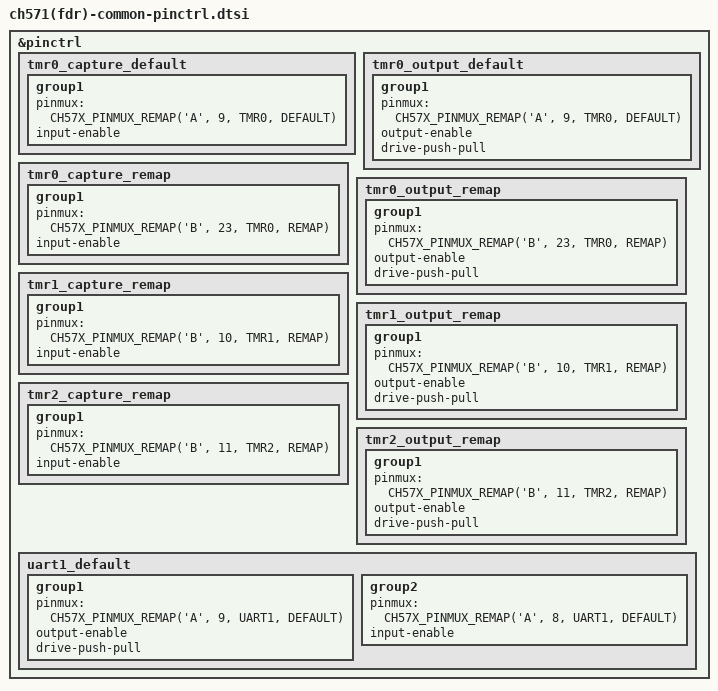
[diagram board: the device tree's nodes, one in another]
/*
 * Copyright (c) 2023 Chen Xingyu <hi@xingrz.me>
 * SPDX-License-Identifier: Apache-2.0
 */

#include <wch/ch57x/ch57x-common-pinctrl.dtsi>
#include <wch/ch57x/ch571-common-pinctrl.dtsi>

&pinctrl {
	/omit-if-no-ref/ tmr0_capture_default: tmr0_capture_default {
		group1 {
			pinmux = <CH57X_PINMUX_REMAP('A', 9, TMR0, DEFAULT)>; /* TMR0 */
			input-enable;
		};
	};

	/omit-if-no-ref/ tmr0_output_default: tmr0_output_default {
		group1 {
			pinmux = <CH57X_PINMUX_REMAP('A', 9, TMR0, DEFAULT)>; /* TMR0 */
			output-enable;
			drive-push-pull;
		};
	};

	/omit-if-no-ref/ tmr0_capture_remap: tmr0_capture_remap {
		group1 {
			pinmux = <CH57X_PINMUX_REMAP('B', 23, TMR0, REMAP)>; /* TMR0_ */
			input-enable;
		};
	};

	/omit-if-no-ref/ tmr0_output_remap: tmr0_output_remap {
		group1 {
			pinmux = <CH57X_PINMUX_REMAP('B', 23, TMR0, REMAP)>; /* TMR0_ */
			output-enable;
			drive-push-pull;
		};
	};

	/omit-if-no-ref/ tmr1_capture_remap: tmr1_capture_remap {
		group1 {
			pinmux = <CH57X_PINMUX_REMAP('B', 10, TMR1, REMAP)>; /* TMR1_ */
			input-enable;
		};
	};

	/omit-if-no-ref/ tmr1_output_remap: tmr1_output_remap {
		group1 {
			pinmux = <CH57X_PINMUX_REMAP('B', 10, TMR1, REMAP)>; /* TMR1_ */
			output-enable;
			drive-push-pull;
		};
	};

	/omit-if-no-ref/ tmr2_capture_remap: tmr2_capture_remap {
		group1 {
			pinmux = <CH57X_PINMUX_REMAP('B', 11, TMR2, REMAP)>; /* TMR2_ */
			input-enable;
		};
	};

	/omit-if-no-ref/ tmr2_output_remap: tmr2_output_remap {
		group1 {
			pinmux = <CH57X_PINMUX_REMAP('B', 11, TMR2, REMAP)>; /* TMR2_ */
			output-enable;
			drive-push-pull;
		};
	};

	/omit-if-no-ref/ uart1_default: uart1_default {
		group1 {
			pinmux = <CH57X_PINMUX_REMAP('A', 9, UART1, DEFAULT)>; /* TXD1 */
			output-enable;
			drive-push-pull;
		};
		group2 {
			pinmux = <CH57X_PINMUX_REMAP('A', 8, UART1, DEFAULT)>; /* RXD1 */
			input-enable;
		};
	};
};
